# LPC55S66_cm33_core1 register map
Vendor: nxp.com; File version: 1.0
CPU: CM33 r2p0, little endian, no MPU, no FPU, VTOR, 3 interrupt priority bits
Registers are 32-bit, read-write, reset 0x0 unless marked. A register's access mark holds for its fields unless they carry their own. Offsets are from the block's base; [hi:lo] are bit positions; {n}, {i} and the like mark numbered series.

## PUF — PUFCTRL
Base 0x4003B000
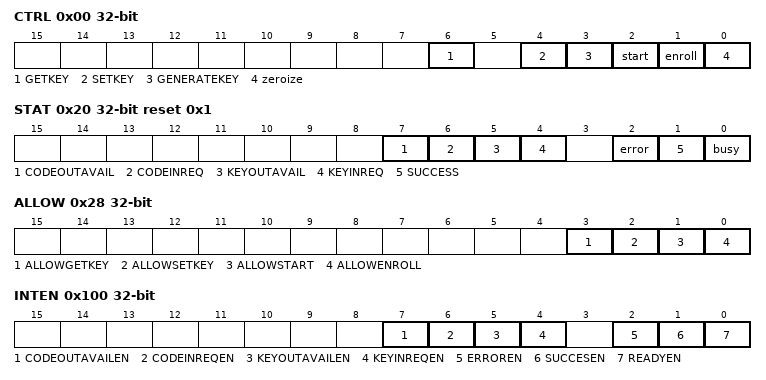
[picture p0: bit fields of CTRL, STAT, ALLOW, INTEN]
0x00 CTRL — PUF Control register
  [6] GETKEY — Begin Get Key operation
  [4] SETKEY — Begin Set User Key operation
  [3] GENERATEKEY — Begin Set Intrinsic Key operation
  [2] start — Begin Start operation
  [1] enroll — Begin Enroll operation
  [0] zeroize — Begin Zeroize operation for PUF and go to Error state
0x04 KEYINDEX — PUF Key Index register
  [3:0] KEYIDX — Key index for Set Key operations
0x08 KEYSIZE — PUF Key Size register
  [5:0] KEYSIZE — Key size for Set Key operations
0x20 STAT reset 0x1 — PUF Status register
  [7] CODEOUTAVAIL ro — Next part of AC/KC is available
  [6] CODEINREQ ro — Request for next part of AC/KC
  [5] KEYOUTAVAIL ro — Next part of key is available
  [4] KEYINREQ ro — Request for next part of key
  [2] error ro — PUF is in the Error state and no operations can be performed
  [1] SUCCESS ro — Last operation was successful
  [0] busy ro — Indicates that operation is in progress
0x28 ALLOW — PUF Allow register
  [3] ALLOWGETKEY ro — Get Key operation is allowed
  [2] ALLOWSETKEY ro — Set Key operations are allowed
  [1] ALLOWSTART ro — Start operation is allowed
  [0] ALLOWENROLL ro — Enroll operation is allowed
0x40 KEYINPUT wo — PUF Key Input register
  [31:0] KEYIN — Key input data
0x44 CODEINPUT wo — PUF Code Input register
  [31:0] CODEIN — AC/KC input data
0x48 CODEOUTPUT ro — PUF Code Output register
  [31:0] CODEOUT — AC/KC output data
0x60 KEYOUTINDEX — PUF Key Output Index register
  [3:0] KEYOUTIDX ro — Key index for the key that is currently output via the Key Output register
0x64 KEYOUTPUT ro — PUF Key Output register
  [31:0] KEYOUT — Key output data
0xDC IFSTAT — PUF Interface Status and clear register
  [0] ERROR — Indicates that an APB error has occurred,Writing logic1 clears the if_error bit
0xFC VERSION ro — PUF version register.
  [31:0] VERSION — Version of the PUF module.
0x100 INTEN — PUF Interrupt Enable
  [7] CODEOUTAVAILEN — Enable corresponding interrupt. Note that bit numbers match those assigned in QK_SR (Quiddikey Status Register)
  [6] CODEINREQEN — Enable corresponding interrupt. Note that bit numbers match those assigned in QK_SR (Quiddikey Status Register)
  [5] KEYOUTAVAILEN — Enable corresponding interrupt. Note that bit numbers match those assigned in QK_SR (Quiddikey Status Register)
  [4] KEYINREQEN — Enable corresponding interrupt. Note that bit numbers match those assigned in QK_SR (Quiddikey Status Register)
  [2] ERROREN — Enable corresponding interrupt. Note that bit numbers match those assigned in QK_SR (Quiddikey Status Register)
  [1] SUCCESEN — Enable corresponding interrupt. Note that bit numbers match those assigned in QK_SR (Quiddikey Status Register)
  [0] READYEN — Enable corresponding interrupt. Note that bit numbers match those assigned in QK_SR (Quiddikey Status Register)
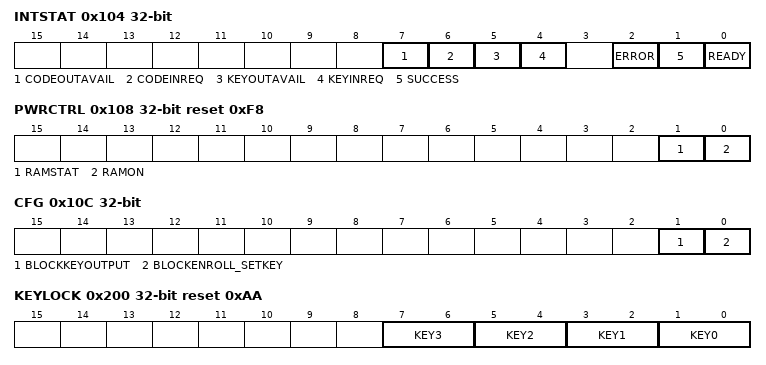
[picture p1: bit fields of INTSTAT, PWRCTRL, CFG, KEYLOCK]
0x104 INTSTAT — PUF interrupt status
  [7] CODEOUTAVAIL — Level sensitive interrupt, cleared when interrupt source clears
  [6] CODEINREQ — Level sensitive interrupt, cleared when interrupt source clears
  [5] KEYOUTAVAIL — Level sensitive interrupt, cleared when interrupt source clears
  [4] KEYINREQ — Level sensitive interrupt, cleared when interrupt source clears
  [2] ERROR — Level sensitive interrupt, cleared when interrupt source clears
  [1] SUCCESS — Level sensitive interrupt, cleared when interrupt source clears
  [0] READY — Triggers on falling edge of busy, write 1 to clear
0x108 PWRCTRL reset 0xF8 (reset mask 0xFD) — PUF RAM Power Control
  [1] RAMSTAT — PUF RAM status.
  [0] RAMON — Power on the PUF RAM.
0x10C CFG — PUF config register for block bits
  [1] BLOCKKEYOUTPUT — Block set key operation. Write 1 to set, cleared on reset.
  [0] BLOCKENROLL_SETKEY — Block enroll operation. Write 1 to set, cleared on reset.
0x200 KEYLOCK reset 0xAA — Only reset in case of full IC reset
  [2n+1:2n] KEY{n} (n=0..3) — "10:Write access to KEY{n}MASK, KEYENABLE.KEY{n} and KEYRESET.KEY{n} is allowed. 00, 01, 11:Write access to KEY{n}MASK, KEYENABLE.KEY{n} and KEYRESET.KEY{n} is NOT allowed. Important Note : Once this field is written with a value different from '10', its value can no longer be modified until un Power On Reset occurs."
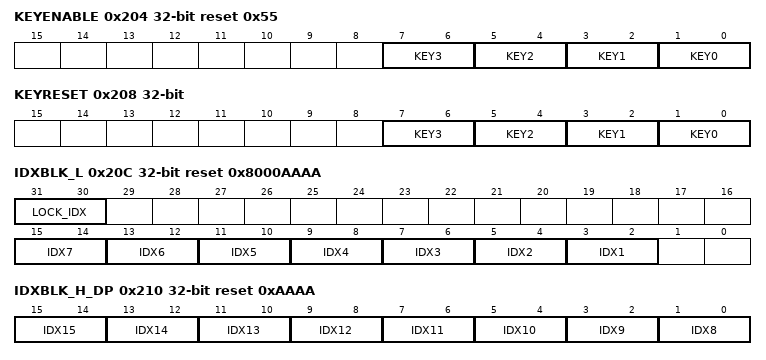
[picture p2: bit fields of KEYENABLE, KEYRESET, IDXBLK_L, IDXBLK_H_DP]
0x204 KEYENABLE reset 0x55
  [2n+1:2n] KEY{n} (n=0..3) — "10: Data coming out from PUF Index 0 interface are shifted in KEY{n} register. 00, 01, 11 : Data coming out from PUF Index 0 interface are NOT shifted in KEY{n} register."
0x208 KEYRESET wo — Reinitialize Keys shift registers counters
  [2n+1:2n] KEY{n} (n=0..3) — 10: Reset KEY{n} shift register. Self clearing. Must be done before loading any new key.
0x20C IDXBLK_L reset 0x8000AAAA
  [31:30] LOCK_IDX wo — Lock 0 to 7 PUF key indexes
  [2n+1:2n] IDX{n} (n=1..7) — Use to block PUF index {n}
0x210 IDXBLK_H_DP reset 0xAAAA
  [2n-15:2n-16] IDX{n} (n=8..15) — Use to block PUF index {n}
{0x214+4i} KEYMASK[{i}] (i=0..3) wo — Only reset in case of full IC reset
  [31:0] KEYMASK
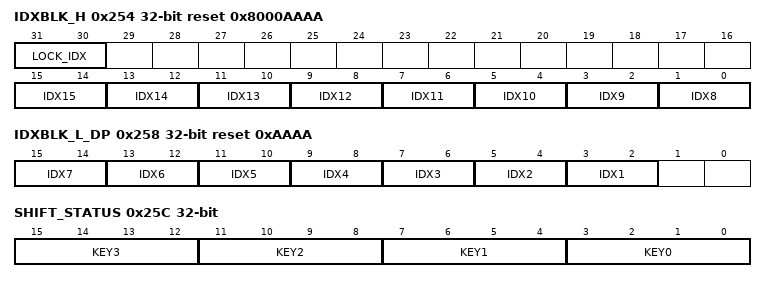
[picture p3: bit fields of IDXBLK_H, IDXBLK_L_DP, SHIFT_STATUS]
0x254 IDXBLK_H reset 0x8000AAAA
  [31:30] LOCK_IDX wo — Lock 8 to 15 PUF key indexes
  [2n-15:2n-16] IDX{n} (n=8..15) — Use to block PUF index {n}
0x258 IDXBLK_L_DP reset 0xAAAA
  [2n+1:2n] IDX{n} (n=1..7) — Use to block PUF index {n}
0x25C SHIFT_STATUS
  [4n+3:4n] KEY{n} ro (n=0..3) — Index counter from key {n} shift register
